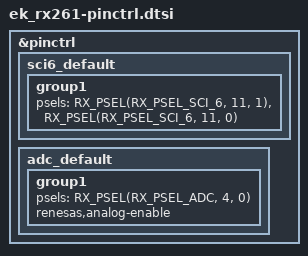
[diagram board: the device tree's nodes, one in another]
/*
 * Copyright (c) 2025 Renesas Electronics Corporation
 *
 * SPDX-License-Identifier: Apache-2.0
 */

&pinctrl {
	sci6_default: sci6_default {
		group1 {
			psels = <RX_PSEL(RX_PSEL_SCI_6, 11, 1)>, /* TX */
				<RX_PSEL(RX_PSEL_SCI_6, 11, 0)>; /* RX */
		};
	};

	adc_default: adc_default {
		group1 {
			/* input */
			psels = <RX_PSEL(RX_PSEL_ADC, 4, 0)>;
			renesas,analog-enable;
		};
	};
};
